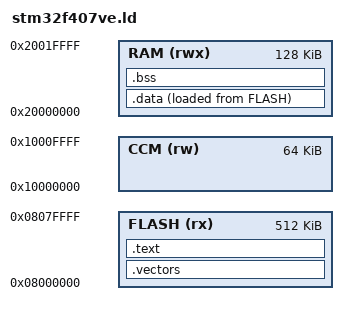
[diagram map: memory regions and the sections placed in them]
/* Copyright (c) 2026 Ricardo Kerschbaumer; SPDX-License-Identifier: MIT */
/* STM32F407VE: 512 KiB of flash, 112 + 16 KiB of SRAM (one block), 64 KiB of CCM data RAM. */
ENTRY(Reset_Handler)
MEMORY {
    FLASH (rx) : ORIGIN = 0x08000000, LENGTH = 512K
    RAM (rwx) : ORIGIN = 0x20000000, LENGTH = 128K
    CCM (rw) : ORIGIN = 0x10000000, LENGTH = 64K
}
_stack_top = ORIGIN(RAM) + LENGTH(RAM);
SECTIONS {
    .vectors : { KEEP(*(.vectors)) } > FLASH
    .text : { *(.text*) *(.rodata*) } > FLASH
    .data : {
        _data_start = .;
        *(.data*)
        . = ALIGN(4);
        _data_end = .;
    } > RAM AT> FLASH
    _data_load = LOADADDR(.data);
    .bss (NOLOAD) : {
        _bss_start = .;
        *(.bss*) *(COMMON)
        . = ALIGN(4);
        _bss_end = .;
    } > RAM
    /DISCARD/ : { *(.comment) *(.ARM.exidx*) *(.ARM.extab*) *(.eh_frame*) }
}
ASSERT(_bss_end <= _stack_top - 1024, "Keep at least 1 KiB for the stack")
